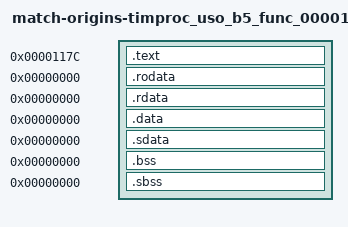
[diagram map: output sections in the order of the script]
/* Standard linker bindings; original USO identity is independently audited. */
SECTIONS {
 .text 0x117c : SUBALIGN(4) { *(.text) *(.text.*) }
 .rodata 0x0 : SUBALIGN(4) { *(.rodata) *(.rodata.*) }
 .rdata 0x0 : SUBALIGN(4) { *(.rdata) *(.rdata.*) }
 .data 0x0 : SUBALIGN(4) { *(.data) *(.data.*) }
 .sdata 0x0 : SUBALIGN(4) { *(.sdata) *(.sdata.*) }
 .bss 0x0 : SUBALIGN(4) { *(.bss) *(.bss.*) }
 .sbss 0x0 : SUBALIGN(4) { *(.sbss) *(.sbss.*) }
 /DISCARD/ : { *(.mdebug) *(.reginfo) *(.pdr) *(.comment) *(.MIPS.abiflags) *(.options) }
}
timproc_uso_b5_func_0000896C = 0x0;
timproc_uso_b5_func_00008AFC = 0x0;
timproc_uso_b5_func_04CCA8 = 0x0;
